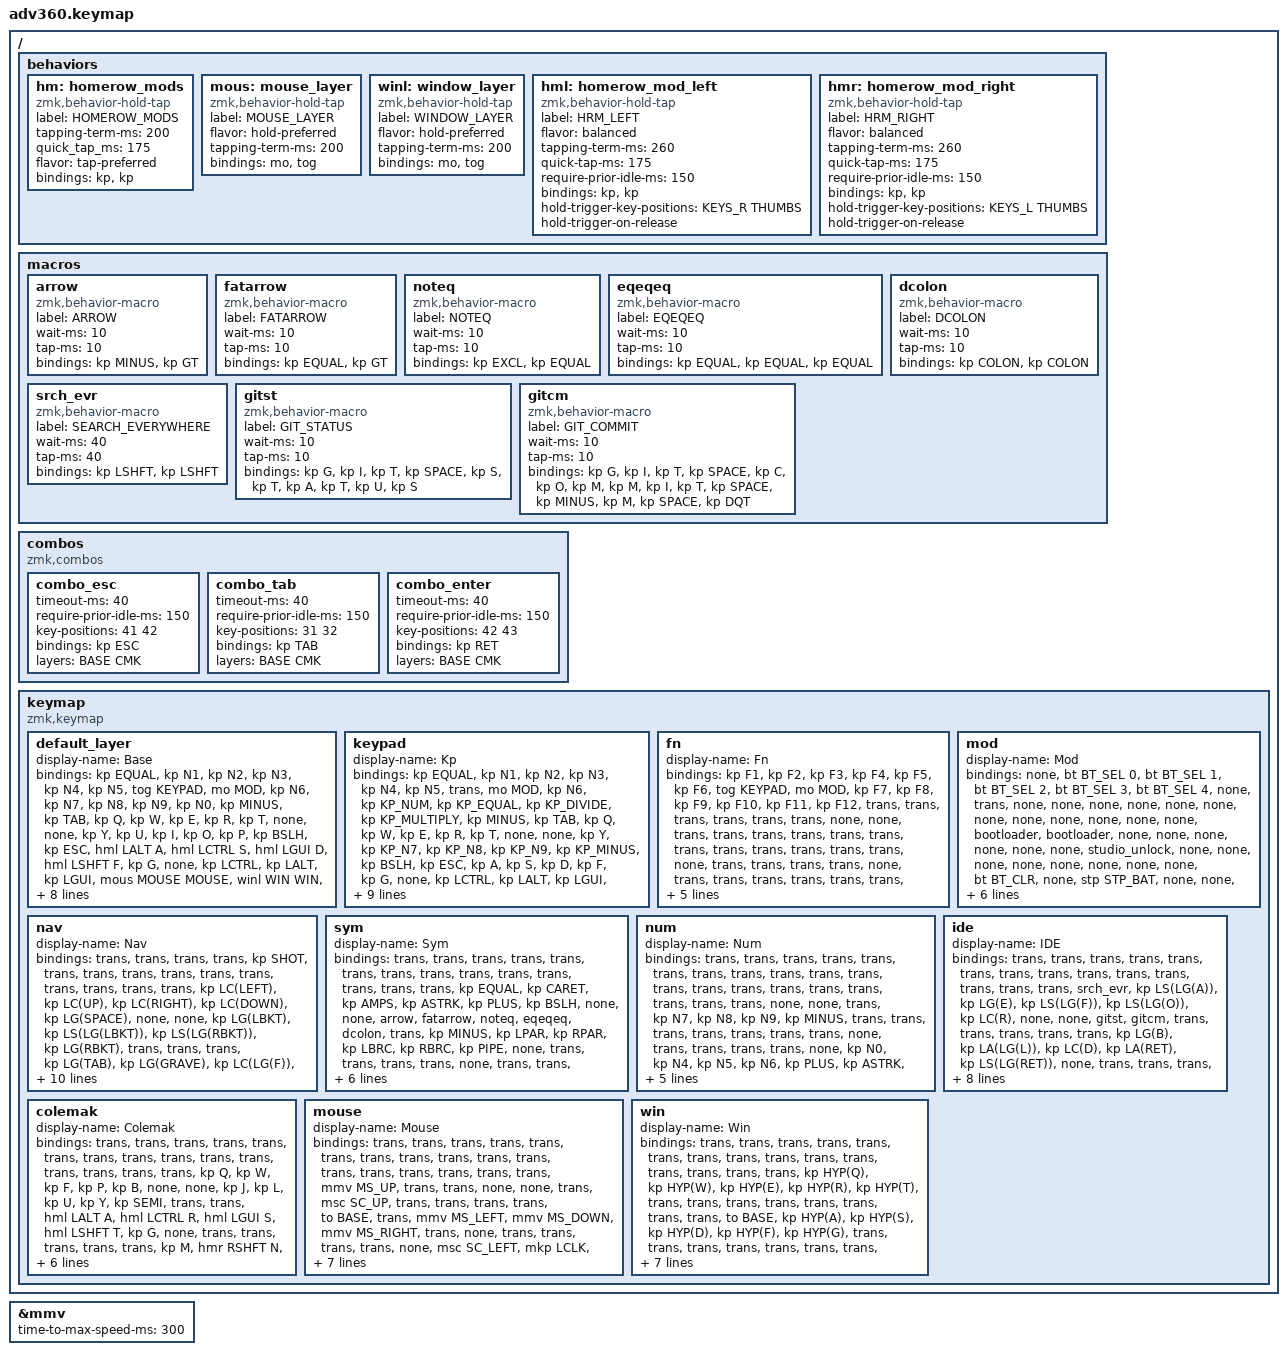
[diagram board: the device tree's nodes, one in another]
#include <behaviors.dtsi>
#include <dt-bindings/zmk/keys.h>
#include <dt-bindings/zmk/bt.h>
#include <dt-bindings/zmk/rgb.h>
#include <dt-bindings/zmk/stp.h>
#include <dt-bindings/zmk/backlight.h>
#include <dt-bindings/zmk/pointing.h>

#define BASE    0
#define KEYPAD  1
#define FN      2
#define MOD     3
#define NAV     4
#define SYM     5
#define NUM     6
#define IDE     7
#define CMK     8
#define MOUSE   9
#define WIN    10

#define KEYS_L  0  1  2  3  4  5  6 14 15 16 17 18 19 20 28 29 30 31 32 33 34 46 47 48 49 50 51 60 61 62 63 64
#define KEYS_R  7  8  9 10 11 12 13 21 22 23 24 25 26 27 39 40 41 42 43 44 45 54 55 56 57 58 59 71 72 73 74 75
#define THUMBS 35 36 37 38 52 53 65 66 67 68 69 70

/* Pointer tuning. MOUSE_SPD is top cursor speed in pixels per second, so 3600
   crosses a 3440px ultrawide in about a second. Raise SCRL_SPD for faster
   scrolling. Ramp-up time lives in the &mmv override at the end of this file. */
#define MOUSE_SPD 3600
#define SCRL_SPD  12
#define MS_UP    MOVE_Y(-MOUSE_SPD)
#define MS_DOWN  MOVE_Y(MOUSE_SPD)
#define MS_LEFT  MOVE_X(-MOUSE_SPD)
#define MS_RIGHT MOVE_X(MOUSE_SPD)
#define SC_UP    MOVE_Y(SCRL_SPD)
#define SC_DOWN  MOVE_Y(-SCRL_SPD)
#define SC_LEFT  MOVE_X(-SCRL_SPD)
#define SC_RIGHT MOVE_X(SCRL_SPD)

/* Hyper = Ctrl+Opt+Cmd+Shift. Nothing in macOS or any app binds four modifiers,
   so the whole family is free for Rectangle Pro. The keyboard is the only thing
   that ever types these, so the chord being unreachable by hand does not matter.
   See KEYMAP.md and bin/rectangle-pro-setup.sh for the other half of this. */
#define HYP(k) LC(LA(LG(LS(k))))

/* macOS region screenshot, drag to select, result lands on the clipboard.
   Drop the LC() to save a file to the desktop instead. */
#define SHOT LC(LS(LG(N4)))

/ {
    behaviors {
      #include "macros.dtsi"
      #include "version.dtsi"

      hm: homerow_mods {
          compatible = "zmk,behavior-hold-tap";
          label = "HOMEROW_MODS";
          #binding-cells = <2>;
          tapping-term-ms = <200>;
          quick_tap_ms = <175>;
          flavor = "tap-preferred";
          bindings = <&kp>, <&kp>;
      };

      mous: mouse_layer {
          compatible = "zmk,behavior-hold-tap";
          label = "MOUSE_LAYER";
          #binding-cells = <2>;
          flavor = "hold-preferred";
          tapping-term-ms = <200>;
          bindings = <&mo>, <&tog>;
      };

      winl: window_layer {
          compatible = "zmk,behavior-hold-tap";
          label = "WINDOW_LAYER";
          #binding-cells = <2>;
          flavor = "hold-preferred";
          tapping-term-ms = <200>;
          bindings = <&mo>, <&tog>;
      };

      hml: homerow_mod_left {
          compatible = "zmk,behavior-hold-tap";
          label = "HRM_LEFT";
          #binding-cells = <2>;
          flavor = "balanced";
          tapping-term-ms = <260>;
          quick-tap-ms = <175>;
          require-prior-idle-ms = <150>;
          bindings = <&kp>, <&kp>;
          hold-trigger-key-positions = <KEYS_R THUMBS>;
          hold-trigger-on-release;
      };

      hmr: homerow_mod_right {
          compatible = "zmk,behavior-hold-tap";
          label = "HRM_RIGHT";
          #binding-cells = <2>;
          flavor = "balanced";
          tapping-term-ms = <260>;
          quick-tap-ms = <175>;
          require-prior-idle-ms = <150>;
          bindings = <&kp>, <&kp>;
          hold-trigger-key-positions = <KEYS_L THUMBS>;
          hold-trigger-on-release;
      };
    };

    macros {
      arrow: arrow {
          compatible = "zmk,behavior-macro";
          #binding-cells = <0>;
          label = "ARROW";
          wait-ms = <10>;
          tap-ms = <10>;
          bindings = <&kp MINUS &kp GT>;
      };
      fatarrow: fatarrow {
          compatible = "zmk,behavior-macro";
          #binding-cells = <0>;
          label = "FATARROW";
          wait-ms = <10>;
          tap-ms = <10>;
          bindings = <&kp EQUAL &kp GT>;
      };
      noteq: noteq {
          compatible = "zmk,behavior-macro";
          #binding-cells = <0>;
          label = "NOTEQ";
          wait-ms = <10>;
          tap-ms = <10>;
          bindings = <&kp EXCL &kp EQUAL>;
      };
      eqeqeq: eqeqeq {
          compatible = "zmk,behavior-macro";
          #binding-cells = <0>;
          label = "EQEQEQ";
          wait-ms = <10>;
          tap-ms = <10>;
          bindings = <&kp EQUAL &kp EQUAL &kp EQUAL>;
      };
      dcolon: dcolon {
          compatible = "zmk,behavior-macro";
          #binding-cells = <0>;
          label = "DCOLON";
          wait-ms = <10>;
          tap-ms = <10>;
          bindings = <&kp COLON &kp COLON>;
      };
      srch_evr: srch_evr {
          compatible = "zmk,behavior-macro";
          #binding-cells = <0>;
          label = "SEARCH_EVERYWHERE";
          wait-ms = <40>;
          tap-ms = <40>;
          bindings = <&kp LSHFT &kp LSHFT>;
      };
      gitst: gitst {
          compatible = "zmk,behavior-macro";
          #binding-cells = <0>;
          label = "GIT_STATUS";
          wait-ms = <10>;
          tap-ms = <10>;
          bindings = <&kp G &kp I &kp T &kp SPACE &kp S &kp T &kp A &kp T &kp U &kp S>;
      };
      gitcm: gitcm {
          compatible = "zmk,behavior-macro";
          #binding-cells = <0>;
          label = "GIT_COMMIT";
          wait-ms = <10>;
          tap-ms = <10>;
          bindings = <&kp G &kp I &kp T &kp SPACE &kp C &kp O &kp M &kp M &kp I &kp T
                      &kp SPACE &kp MINUS &kp M &kp SPACE &kp DQT>;
      };
    };

    combos {
      compatible = "zmk,combos";

      combo_esc {
          timeout-ms = <40>;
          require-prior-idle-ms = <150>;
          key-positions = <41 42>;
          bindings = <&kp ESC>;
          layers = <BASE CMK>;
      };
      combo_tab {
          timeout-ms = <40>;
          require-prior-idle-ms = <150>;
          key-positions = <31 32>;
          bindings = <&kp TAB>;
          layers = <BASE CMK>;
      };
      combo_enter {
          timeout-ms = <40>;
          require-prior-idle-ms = <150>;
          key-positions = <42 43>;
          bindings = <&kp RET>;
          layers = <BASE CMK>;
      };
    };

  keymap {
    compatible = "zmk,keymap";

    default_layer {
      display-name = "Base";
      bindings = <
        &kp EQUAL &kp N1    &kp N2      &kp N3       &kp N4       &kp N5 &tog KEYPAD                                                        &mo MOD &kp N6 &kp N7        &kp N8        &kp N9       &kp N0         &kp MINUS
        &kp TAB   &kp Q     &kp W       &kp E        &kp R        &kp T  &none                                                              &none   &kp Y  &kp U         &kp I         &kp O        &kp P          &kp BSLH
        &kp ESC   &hml LALT A &hml LCTRL S &hml LGUI  D &hml LSHFT F &kp G &none         &kp LCTRL &kp LALT &kp LGUI &mous MOUSE MOUSE               &winl WIN WIN &kp H  &hmr RSHFT J  &hmr RGUI  K  &hmr RCTRL L  &hmr RALT SEMI &kp SQT
        &kp LSHFT &kp Z     &kp X       &kp C        &kp V        &kp B                           &mo NUM  &mo SYM                                  &kp N  &kp M         &kp COMMA     &kp DOT      &kp FSLH       &kp RSHFT
        &mo FN    &kp GRAVE &caps_word  &kp LEFT     &kp RIGHT               &kp SPACE &lt NAV DEL &sl NUM  &mo IDE  &kp ENTER &kp BSPC                    &kp UP        &kp DOWN      &kp LBKT     &kp RBKT       &mo FN
      >;
    };

    keypad {
      display-name = "Kp";
      bindings = <
        &kp EQUAL &kp N1    &kp N2   &kp N3   &kp N4     &kp N5 &trans                                                           &mo MOD &kp N6 &kp KP_NUM &kp KP_EQUAL &kp KP_DIVIDE &kp KP_MULTIPLY &kp MINUS
        &kp TAB   &kp Q     &kp W    &kp E    &kp R      &kp T  &none                                                            &none   &kp Y  &kp KP_N7  &kp KP_N8    &kp KP_N9     &kp KP_MINUS    &kp BSLH
        &kp ESC   &kp A     &kp S    &kp D    &kp F      &kp G  &none           &kp LCTRL &kp LALT &kp LGUI  &kp RCTRL           &trans  &kp H  &kp KP_N4  &kp KP_N5    &kp KP_N6     &kp KP_PLUS     &kp SQT
        &kp LSHFT &kp Z     &kp X    &kp C    &kp V      &kp B                            &kp HOME &kp PG_UP                             &kp N  &kp KP_N1  &kp KP_N2    &kp KP_N3     &kp KP_ENTER    &kp RSHFT
        &mo FN    &kp GRAVE &kp CAPS &kp LEFT &kp RIGHT                &kp SPACE &kp KP_N0   &kp END  &kp PG_DN &kp ENTER &kp BSPC                &kp UP     &kp DOWN     &kp KP_DOT    &kp RBKT        &mo FN
      >;
    };

    fn {
      display-name = "Fn";
      bindings = <
        &kp F1 &kp F2 &kp F3 &kp F4 &kp F5 &kp F6 &tog KEYPAD                                      &mo MOD &kp F7 &kp F8 &kp F9 &kp F10 &kp F11 &kp F12
        &trans &trans &trans &trans &trans &trans &none                                            &none   &trans &trans &trans &trans  &trans  &trans
        &trans &trans &trans &trans &trans &trans &none        &trans &trans &trans &trans         &none   &trans &trans &trans &trans  &trans  &trans
        &trans &trans &trans &trans &trans &trans                     &trans &trans                        &trans &trans &trans &trans  &trans  &trans
        &trans &trans &trans &trans &trans              &trans &trans &trans &trans &trans &trans                 &trans &trans &trans  &trans  &trans
      >;
    };

    mod {
      display-name = "Mod";
      bindings = <
        &none          &bt BT_SEL 0 &bt BT_SEL 1 &bt BT_SEL 2 &bt BT_SEL 3 &bt BT_SEL 4 &none                                                     &trans          &none        &none      &none      &none &none &none
        &none          &none        &none        &none        &none        &none        &bootloader                                               &bootloader     &none        &none      &none      &none &none &none
        &studio_unlock &none        &none        &none        &none        &none        &none        &none &none      &bt BT_CLR      &none        &stp STP_BAT    &none        &none      &none      &none &none &none
        &none          &none        &none        &none        &macro_ver   &none                           &none      &none                                       &none        &none      &none      &none &none &none
        &none          &none        &tog CMK     &none        &none                     &none &none        &none      &none           &bl BL_TOG  &rgb_ug RGB_TOG              &bl BL_INC &bl BL_DEC &none &none &none
      >;
    };

    nav {
      display-name = "Nav";
      bindings = <
        &trans &trans        &trans        &trans          &kp SHOT      &trans        &trans                                    &trans &trans        &trans            &trans            &trans        &trans     &trans
        &trans &kp LC(LEFT)  &kp LC(UP)    &kp LC(RIGHT)   &kp LC(DOWN)  &kp LG(SPACE) &none                                     &none  &kp LG(LBKT)  &kp LS(LG(LBKT))  &kp LS(LG(RBKT))  &kp LG(RBKT)  &trans     &trans
        &trans &kp LG(TAB)   &kp LG(GRAVE) &kp LC(LG(F))   &kp F11       &kp LG(M)     &none    &trans &trans &trans &trans      &none  &kp LEFT      &kp DOWN          &kp UP            &kp RIGHT     &kp LC(A)  &kp LC(E)
        &trans &kp LG(Z)     &kp LG(X)     &kp LG(C)       &kp LG(V)     &trans                        &trans &trans                    &kp LG(LEFT)  &kp LA(LEFT)      &kp LA(RIGHT)     &kp LG(RIGHT) &trans     &trans
        &trans &trans        &trans        &trans          &trans                 &trans &trans        &trans &trans &trans &trans             &kp PG_UP         &kp PG_DN         &trans        &trans     &trans
      >;
    };

    sym {
      display-name = "Sym";
      bindings = <
        &trans     &trans     &trans     &trans     &trans     &trans     &trans                                        &trans &trans  &trans     &trans  &trans    &trans   &trans
        &kp EQUAL  &kp CARET  &kp AMPS   &kp ASTRK  &kp PLUS   &kp BSLH   &none                                         &none  &arrow  &fatarrow  &noteq  &eqeqeq   &dcolon  &trans
        &kp MINUS  &kp LPAR   &kp RPAR   &kp LBRC   &kp RBRC   &kp PIPE   &none    &trans &trans &trans &trans          &none  &trans  &trans     &trans  &trans    &trans   &trans
        &trans     &kp LBKT   &kp RBKT   &kp LT     &kp GT     &kp TILDE                  &trans &trans                        &trans  &trans     &trans  &trans    &trans   &trans
        &trans     &trans     &trans     &trans     &trans                 &trans &trans  &trans &trans &trans &trans                  &trans     &trans  &trans    &trans   &trans
      >;
    };

    num {
      display-name = "Num";
      bindings = <
        &trans &trans &trans &trans &trans &trans &trans                                     &trans &trans     &trans     &trans   &trans    &trans       &trans
        &trans &trans &trans &trans &trans &trans &none                                      &none  &trans     &kp N7     &kp N8   &kp N9    &kp MINUS    &trans
        &trans &trans &trans &trans &trans &trans &none    &trans &trans &trans &trans       &none  &kp N0     &kp N4     &kp N5   &kp N6    &kp PLUS     &kp ASTRK
        &trans &trans &trans &trans &trans &trans                &trans &trans                      &kp COMMA  &kp N1     &kp N2   &kp N3    &kp DOT      &trans
        &trans &trans &trans &trans &trans        &trans &trans   &trans &trans &trans &trans                  &trans     &trans   &trans    &trans       &trans
      >;
    };

    ide {
      display-name = "IDE";
      bindings = <
        &trans     &trans           &trans        &trans           &trans           &trans     &trans                                  &trans &trans  &trans  &trans     &trans        &trans       &trans
        &srch_evr  &kp LS(LG(A))    &kp LG(E)     &kp LS(LG(F))    &kp LS(LG(O))    &kp LC(R)  &none                                   &none  &gitst  &gitcm  &trans     &trans        &trans       &trans
        &trans     &kp LG(B)        &kp LA(LG(L)) &kp LC(D)        &kp LA(RET)      &kp LS(LG(RET)) &none  &trans &trans &trans &trans &none  &kp F7  &kp F8  &kp LS(F8) &kp LA(LG(R)) &kp LG(F8)   &trans
        &trans     &kp LS(F6)       &kp LA(LG(T)) &kp LA(LG(V))    &kp LA(LG(M))    &kp LA(LG(B))          &trans &trans                      &trans  &trans  &trans     &trans        &trans       &trans
        &trans     &trans           &trans        &trans           &trans                  &trans &trans   &trans &trans &trans &trans                &trans  &trans     &trans        &trans       &trans
      >;
    };

    colemak {
      display-name = "Colemak";
      bindings = <
        &trans &trans      &trans      &trans      &trans      &trans &trans                                          &trans &trans &trans        &trans        &trans       &trans         &trans
        &trans &kp Q       &kp W       &kp F       &kp P       &kp B  &none                                           &none  &kp J  &kp L         &kp U         &kp Y        &kp SEMI       &trans
        &trans &hml LALT A &hml LCTRL R &hml LGUI  S &hml LSHFT T &kp G &none      &trans &trans &trans &trans          &trans &kp M  &hmr RSHFT N  &hmr RGUI  E  &hmr RCTRL I  &hmr RALT O    &trans
        &trans &kp Z       &kp X       &kp C       &kp D       &kp V                     &trans &trans                        &kp K  &kp H         &kp COMMA     &kp DOT      &kp FSLH       &trans
        &trans &trans      &trans      &trans      &trans             &trans &trans      &trans &trans &trans &trans                 &trans        &trans        &trans       &trans         &trans
      >;
    };

    mouse {
      display-name = "Mouse";
      bindings = <
        &trans   &trans &trans       &trans        &trans        &trans &trans                                     &trans &trans       &trans       &trans    &trans    &trans        &trans
        &trans   &trans &trans       &mmv MS_UP    &trans        &trans &none                                      &none  &trans       &msc SC_UP   &trans    &trans    &trans        &trans
        &to BASE &trans &mmv MS_LEFT &mmv MS_DOWN  &mmv MS_RIGHT &trans &none    &trans &trans &trans &trans        &none  &msc SC_LEFT &mkp LCLK    &mkp RCLK &mkp MCLK &msc SC_RIGHT &trans
        &trans   &trans &trans       &trans        &trans        &trans                  &trans &trans                     &trans       &msc SC_DOWN &trans    &trans    &trans        &trans
        &trans   &trans &trans       &trans        &trans                 &trans &trans  &trans &trans &trans &trans                    &trans       &trans    &trans    &trans        &trans
      >;
    };

    win {
      display-name = "Win";
      bindings = <
        &trans   &trans          &trans          &trans          &trans          &trans          &trans                                    &trans &trans &trans &trans &trans &trans &trans
        &trans   &kp HYP(Q)      &kp HYP(W)      &kp HYP(E)      &kp HYP(R)      &kp HYP(T)      &trans                                    &trans &trans &trans &trans &trans &trans &trans
        &to BASE &kp HYP(A)      &kp HYP(S)      &kp HYP(D)      &kp HYP(F)      &kp HYP(G)      &trans   &trans &trans &trans &trans      &trans &trans &trans &trans &trans &trans &trans
        &trans   &kp HYP(Z)      &kp HYP(X)      &kp HYP(C)      &kp HYP(V)      &kp HYP(B)               &trans &trans                           &trans &trans &trans &trans &trans &trans
        &trans   &kp HYP(Y)      &kp HYP(U)      &kp HYP(I)      &kp HYP(O)              &trans &trans    &trans &trans &trans &trans                    &trans &trans &trans &trans &trans
      >;
    };

  };
};

/* Cursor ramp: starts slow for precision, reaches MOUSE_SPD after this long.
   Kept short so the higher top speed is actually reachable in a quick press. */
&mmv {
    time-to-max-speed-ms = <300>;
};
